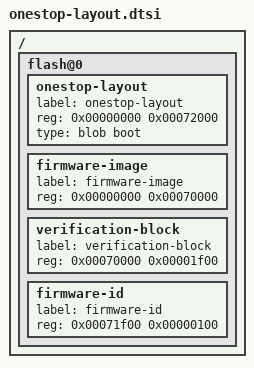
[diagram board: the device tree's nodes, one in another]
/*
 * Copyright (c) 2011 The Chromium OS Authors. All rights reserved.
 * Use of this source code is governed by a BSD-style license that can be
 * found in the LICENSE file.
 */

/*
 * This is a flash map (fmap) defines the internal layout of onestop blobs
 * in R/W slot A and slot B. Given that, the addresses here are interpreted
 * as relative offset from its enclosing onestop blob.
 *
 * The onestop layout is made smaller than 512 KB so that two onestop blobs
 * together are smaller than 1 MB and it is possible to squeeze the entire
 * R/W section into 1 MB (the R/W section includes two onestop blobs and
 * read-write data blobs).
 */

/ {
	flash@0 {
		/* total size of onestop blob: ~468 KB */
		onestop-layout {
			label = "onestop-layout";
			reg = <0x00000000 0x00072000>;
			type = "blob boot";
		};

		/* U-Boot image including fdt: ~460 KB */
		firmware-image {
			label = "firmware-image";
			reg = <0x00000000 0x00070000>;
		};

		/* verification block: ~8 KB */
		verification-block {
			label = "verification-block";
			reg = <0x00070000 0x00001f00>;
		};

		/* frimware ID: 256 Bytes */
		firmware-id {
			label = "firmware-id";
			reg = <0x00071f00 0x00000100>;
		};
	};
};
